# XHSC_HC32F420 register map
Vendor: XHSC Co.Ltd; Series: ARMCM4; File version: 1.2
CPU: CM4 r0p0, little endian, no MPU, no FPU, 3 interrupt priority bits
Registers are 32-bit, read-write, reset 0x0 unless marked. A register's access mark holds for its fields unless they carry their own. Offsets are from the block's base; [hi:lo] are bit positions; {n}, {i} and the like mark numbered series; 'fields as' and 'values as' point back to an identical list.

## I2C0 — desc I2C
Base 0x40002800
Same registers: I2C1 0x40002C00
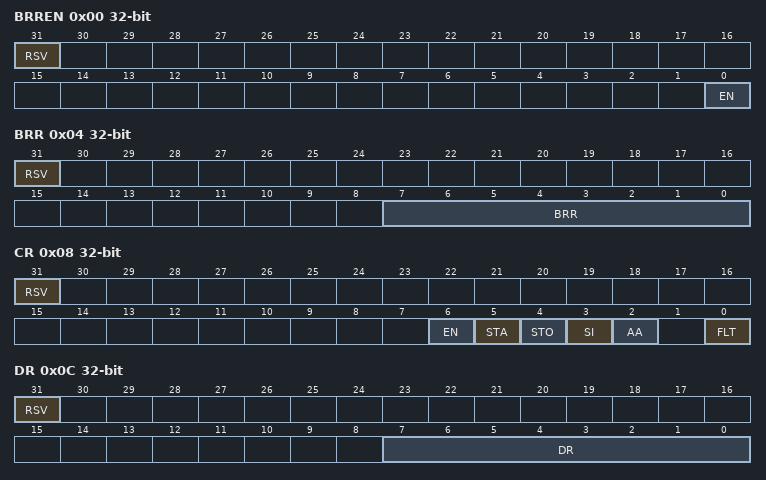
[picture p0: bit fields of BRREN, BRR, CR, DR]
0x00 BRREN (reset mask 0x1)
  [31] RSV, [0] EN
0x04 BRR (reset mask 0xFF)
  [31] RSV, [7:0] BRR
0x08 CR (reset mask 0x7D)
  [31] RSV, [6] EN, [5] STA, [4] STO, [3] SI, [2] AA, [0] FLT
0x0C DR (reset mask 0xFF)
  [31] RSV, [7:0] DR
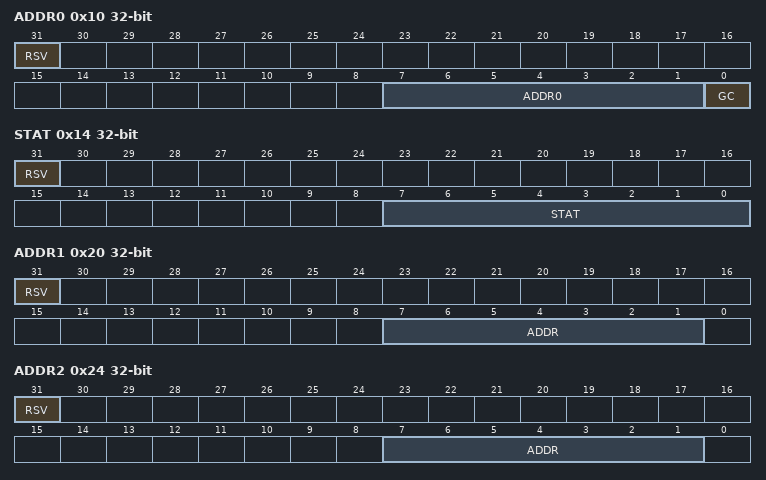
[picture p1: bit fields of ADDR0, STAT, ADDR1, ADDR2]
0x10 ADDR0 (reset mask 0xFF)
  [31] RSV, [7:1] ADDR0, [0] GC
0x14 STAT ro (reset mask 0xFF)
  [31] RSV, [7:0] STAT
0x20 ADDR1 (reset mask 0xFF)
  [31] RSV, [7:1] ADDR
0x24 ADDR2 (reset mask 0xFF)
  [31] RSV, [7:1] ADDR
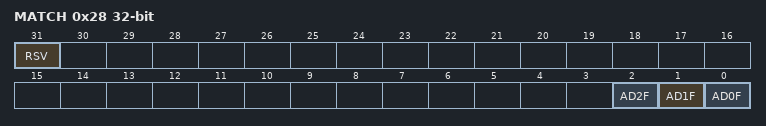
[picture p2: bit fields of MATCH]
0x28 MATCH ro (reset mask 0xFF)
  [31] RSV, [2] AD2F, [1] AD1F, [0] AD0F

## IWDT
Base 0x40008C80
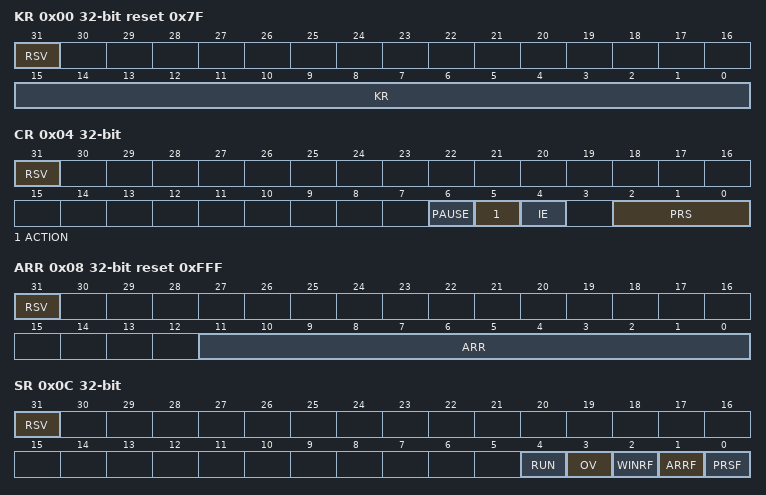
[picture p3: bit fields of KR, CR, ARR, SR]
0x00 KR wo reset 0x7F (reset mask 0xFF)
  [31] RSV, [15:0] KR
0x04 CR (reset mask 0xFF)
  [31] RSV, [6] PAUSE, [5] ACTION, [4] IE, [2:0] PRS
0x08 ARR reset 0xFFF (reset mask 0xFFF)
  [31] RSV, [11:0] ARR
0x0C SR (reset mask 0x1F)
  [31] RSV ro, [4] RUN ro, [3] OV, [2] WINRF ro, [1] ARRF ro, [0] PRSF ro
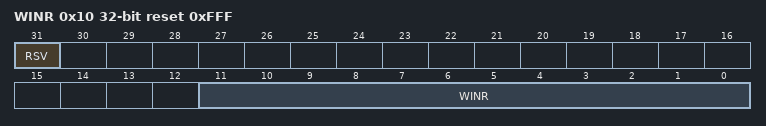
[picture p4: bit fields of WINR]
0x10 WINR reset 0xFFF (reset mask 0xFFF)
  [31] RSV, [11:0] WINR

## LVD
Base 0x4000AA00
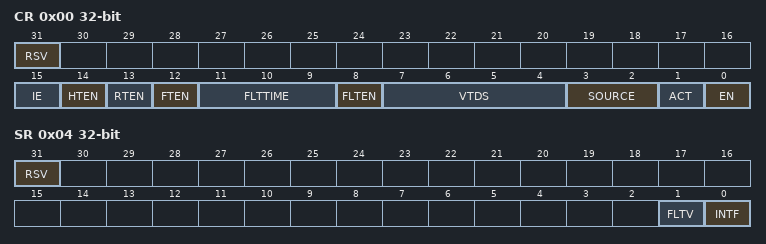
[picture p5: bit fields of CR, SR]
0x00 CR (reset mask 0xFFFF)
  [31] RSV, [15] IE, [14] HTEN, [13] RTEN, [12] FTEN, [11:9] FLTTIME, [8] FLTEN, [7:4] VTDS, [3:2] SOURCE, [1] ACT, [0] EN
0x04 SR (reset mask 0xFFFF)
  [31] RSV, [1] FLTV, [0] INTF

## SPI0 — desc SPI
Base 0x40003800
Same registers: SPI1 0x40003C00
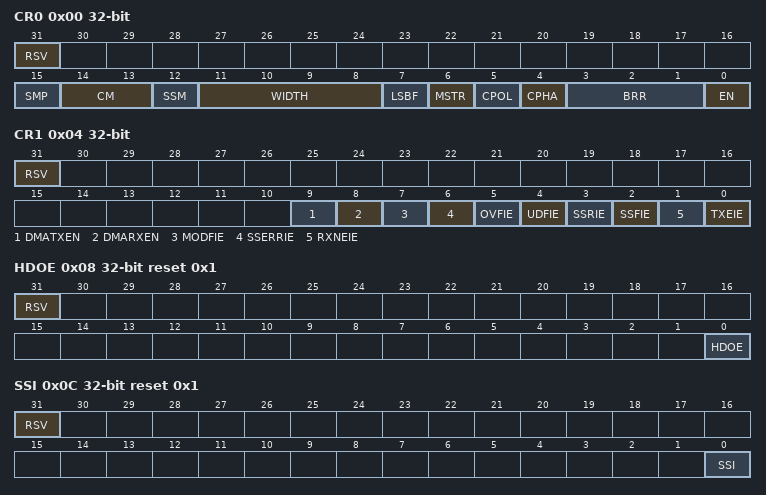
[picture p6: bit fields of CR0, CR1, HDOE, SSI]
0x00 CR0 (reset mask 0xDF)
  [31] RSV, [15] SMP, [14:13] CM, [12] SSM, [11:8] WIDTH, [7] LSBF, [6] MSTR, [5] CPOL, [4] CPHA, [3:1] BRR, [0] EN
0x04 CR1 (reset mask 0xDF)
  [31] RSV, [9] DMATXEN, [8] DMARXEN, [7] MODFIE, [6] SSERRIE, [5] OVFIE, [4] UDFIE, [3] SSRIE, [2] SSFIE, [1] RXNEIE, [0] TXEIE
0x08 HDOE reset 0x1 (reset mask 0x1)
  [31] RSV, [0] HDOE
0x0C SSI reset 0x1 (reset mask 0x1)
  [31] RSV, [0] SSI
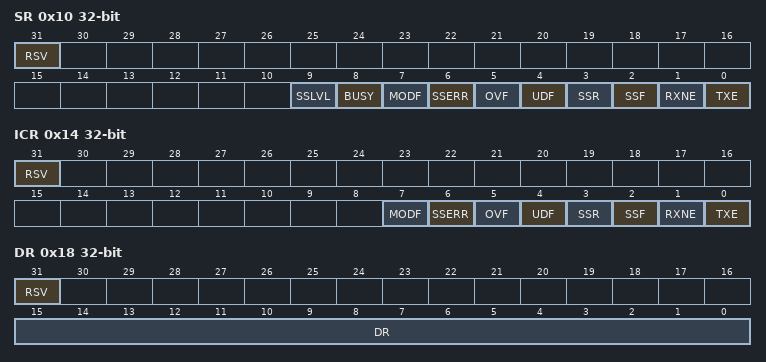
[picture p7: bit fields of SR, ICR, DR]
0x10 SR ro (reset mask 0xBE)
  [31] RSV, [9] SSLVL, [8] BUSY, [7] MODF, [6] SSERR, [5] OVF, [4] UDF, [3] SSR, [2] SSF, [1] RXNE, [0] TXE
0x14 ICR wo (reset mask 0xBE)
  [31] RSV, [7] MODF, [6] SSERR, [5] OVF, [4] UDF, [3] SSR, [2] SSF, [1] RXNE, [0] TXE
0x18 DR (reset mask 0xFF)
  [31] RSV, [15:0] DR

## SYSCTRL
Base 0x4000B800; alternate view of GPIOAUX
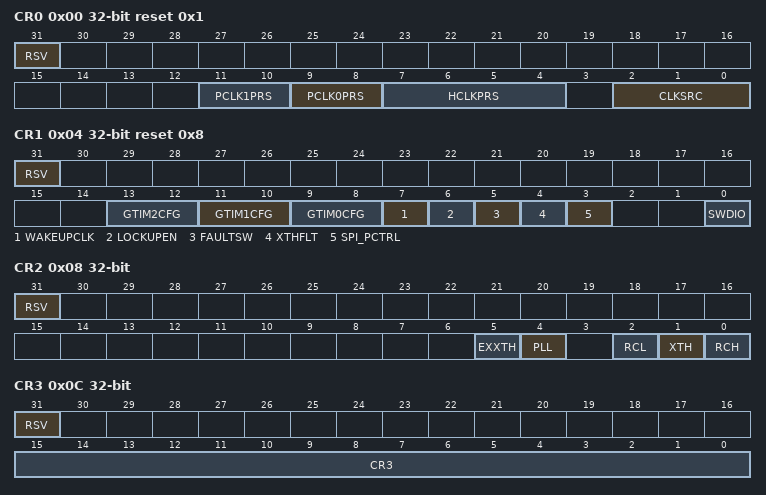
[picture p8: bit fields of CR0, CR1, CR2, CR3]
0x00 CR0 reset 0x1 (reset mask 0x9FFF)
  [31] RSV, [11:10] PCLK1PRS, [9:8] PCLK0PRS, [7:4] HCLKPRS, [2:0] CLKSRC
0x04 CR1 reset 0x8 (reset mask 0xF7E)
  [31] RSV, [13:12] GTIM2CFG, [11:10] GTIM1CFG, [9:8] GTIM0CFG, [7] WAKEUPCLK, [6] LOCKUPEN, [5] FAULTSW, [4] XTHFLT, [3] SPI_PCTRL, [0] SWDIO
0x08 CR2 (reset mask 0xFFFF)
  [31] RSV, [5] EXXTH, [4] PLL, [2] RCL, [1] XTH, [0] RCH
0x0C CR3 wo (reset mask 0xFFFF)
  [31] RSV, [15:0] CR3
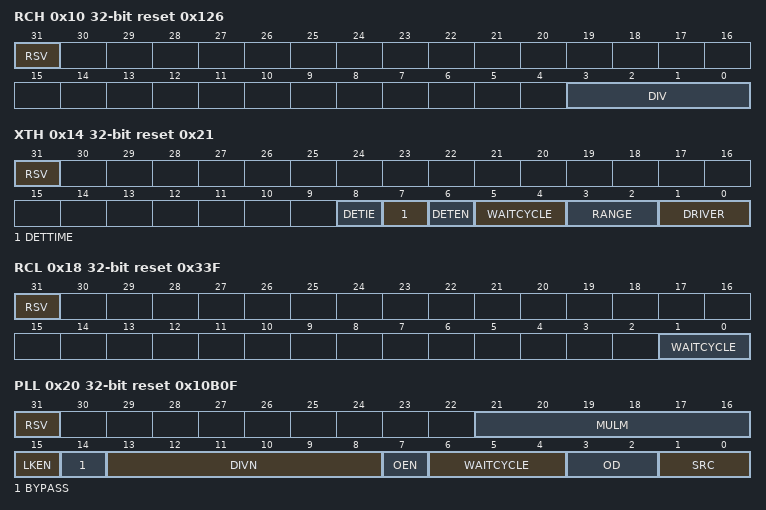
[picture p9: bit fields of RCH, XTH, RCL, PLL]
0x10 RCH reset 0x126 (reset mask 0xFFF)
  [31] RSV, [3:0] DIV
0x14 XTH reset 0x21 (reset mask 0x7F)
  [31] RSV, [8] DETIE, [7] DETTIME, [6] DETEN, [5:4] WAITCYCLE, [3:2] RANGE, [1:0] DRIVER
0x18 RCL reset 0x33F (reset mask 0x1FFF)
  [31] RSV, [1:0] WAITCYCLE
0x20 PLL reset 0x10B0F (reset mask 0x3FFFF)
  [31] RSV, [21:16] MULM, [15] LKEN, [14] BYPASS, [13:8] DIVN, [7] OEN, [6:4] WAITCYCLE, [3:2] OD, [1:0] SRC
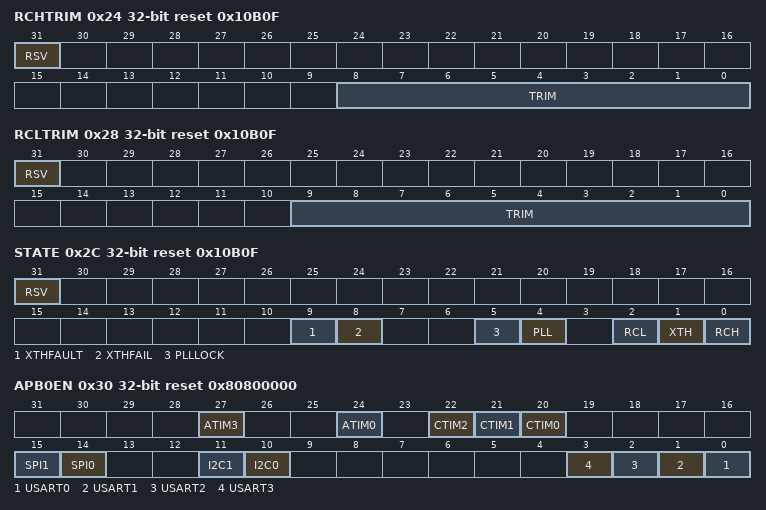
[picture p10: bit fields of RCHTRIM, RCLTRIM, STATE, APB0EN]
0x24 RCHTRIM reset 0x10B0F (reset mask 0x3FFFF)
  [31] RSV, [8:0] TRIM
0x28 RCLTRIM reset 0x10B0F (reset mask 0x3FFFF)
  [31] RSV, [9:0] TRIM
0x2C STATE reset 0x10B0F (reset mask 0x3FFFF)
  [31] RSV, [9] XTHFAULT, [8] XTHFAIL, [5] PLLLOCK, [4] PLL, [2] RCL, [1] XTH, [0] RCH
0x30 APB0EN reset 0x80800000
  [27] ATIM3, [24] ATIM0, [22] CTIM2, [21] CTIM1, [20] CTIM0, [15] SPI1, [14] SPI0, [11] I2C1, [10] I2C0, [n] USART{n} (n=0..3)
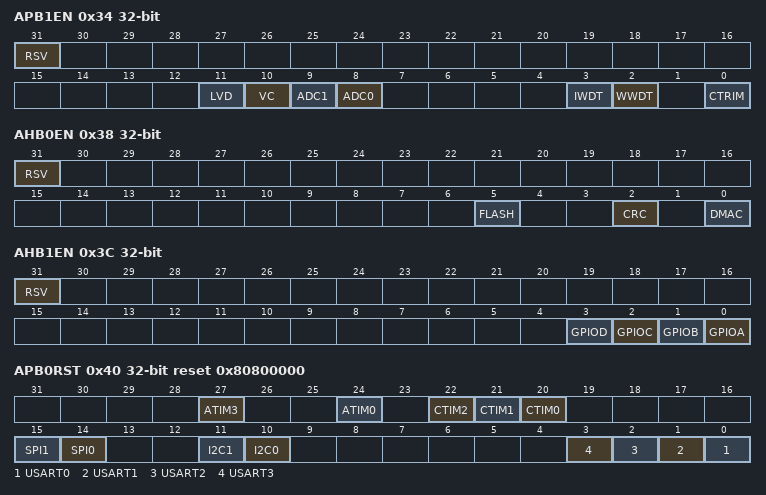
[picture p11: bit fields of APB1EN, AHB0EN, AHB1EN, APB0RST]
0x34 APB1EN (reset mask 0xFFF)
  [31] RSV, [11] LVD, [10] VC, [9] ADC1, [8] ADC0, [3] IWDT, [2] WWDT, [0] CTRIM
0x38 AHB0EN (reset mask 0xFFF)
  [31] RSV, [5] FLASH, [2] CRC, [0] DMAC
0x3C AHB1EN (reset mask 0xFFF)
  [31] RSV, [3] GPIOD, [2] GPIOC, [1] GPIOB, [0] GPIOA
0x40 APB0RST reset 0x80800000
  fields as APB0EN
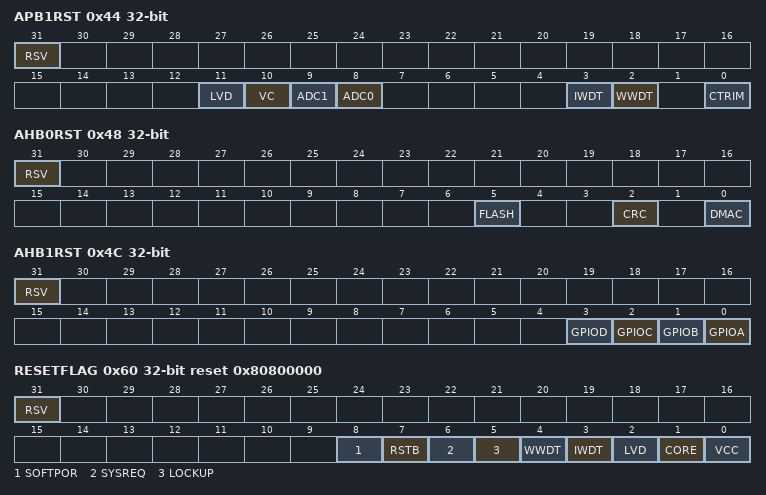
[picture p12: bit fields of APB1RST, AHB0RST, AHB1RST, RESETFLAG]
0x44 APB1RST (reset mask 0xFFF)
  fields as APB1EN
0x48 AHB0RST (reset mask 0xFFF)
  [31] RSV, [5] FLASH, [2] CRC, [0] DMAC
0x4C AHB1RST (reset mask 0xFFF)
  [31] RSV, [3] GPIOD, [2] GPIOC, [1] GPIOB, [0] GPIOA
0x60 RESETFLAG reset 0x80800000
  [31] RSV, [8] SOFTPOR, [7] RSTB, [6] SYSREQ, [5] LOCKUP, [4] WWDT, [3] IWDT, [2] LVD, [1] CORE, [0] VCC
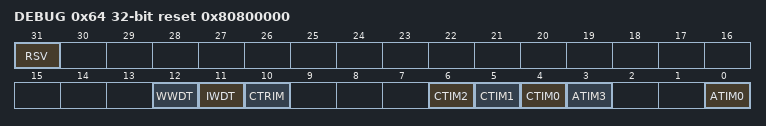
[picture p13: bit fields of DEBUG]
0x64 DEBUG reset 0x80800000 (reset mask 0xFF7FEFFF)
  [31] RSV, [12] WWDT, [11] IWDT, [10] CTRIM, [6] CTIM2, [5] CTIM1, [4] CTIM0, [3] ATIM3, [0] ATIM0

## USART0 — desc USART
Base 0x40000000
Same registers: USART1 0x40000400, USART2 0x40000800, USART3 0x40000C00
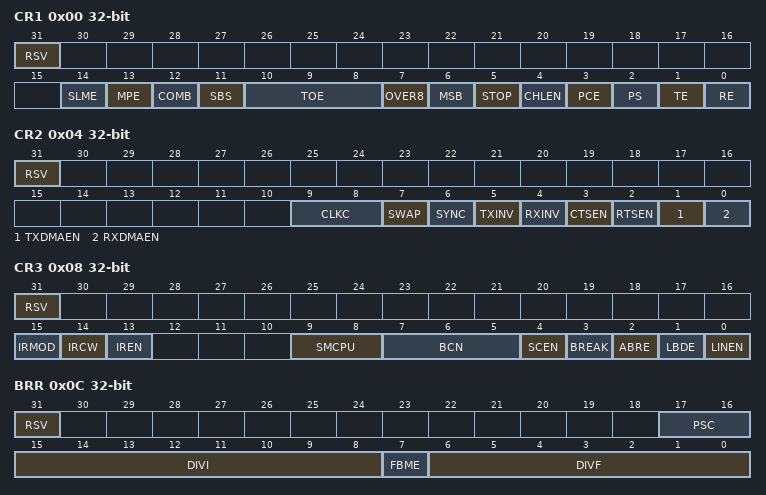
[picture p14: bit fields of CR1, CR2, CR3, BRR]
0x00 CR1 (reset mask 0xFFFF)
  [31] RSV, [14] SLME, [13] MPE, [12] COMB, [11] SBS, [10:8] TOE, [7] OVER8, [6] MSB, [5] STOP, [4] CHLEN, [3] PCE, [2] PS, [1] TE, [0] RE
0x04 CR2 (reset mask 0xFFFF)
  [31] RSV, [9:8] CLKC, [7] SWAP, [6] SYNC, [5] TXINV, [4] RXINV, [3] CTSEN, [2] RTSEN, [1] TXDMAEN, [0] RXDMAEN
0x08 CR3 (reset mask 0xFFFF)
  [31] RSV, [15] IRMOD, [14] IRCW, [13] IREN, [9:8] SMCPU, [7:5] BCN, [4] SCEN, [3] BREAK, [2] ABRE, [1] LBDE, [0] LINEN
0x0C BRR (reset mask 0xFFFF)
  [31] RSV, [17:16] PSC, [15:8] DIVI, [7] FBME, [6:0] DIVF
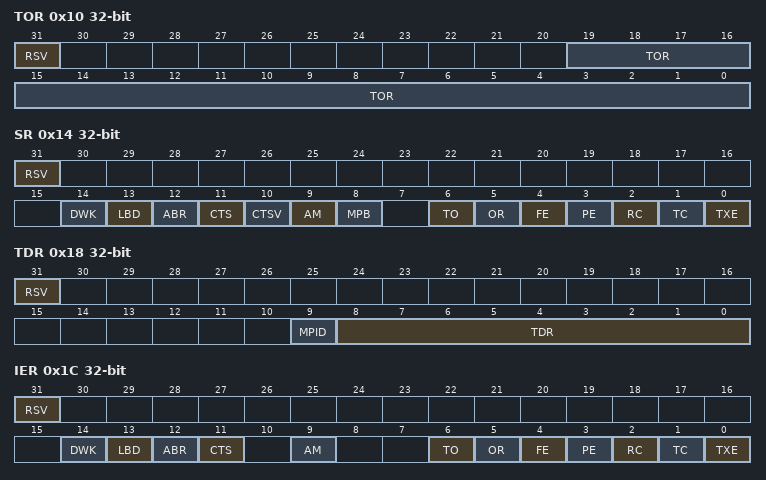
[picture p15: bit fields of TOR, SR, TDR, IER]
0x10 TOR (reset mask 0xFFFFF)
  [31] RSV, [19:0] TOR
0x14 SR ro (reset mask 0xFFFF)
  [31] RSV, [14] DWK, [13] LBD, [12] ABR, [11] CTS, [10] CTSV, [9] AM, [8] MPB, [6] TO, [5] OR, [4] FE, [3] PE, [2] RC, [1] TC, [0] TXE
0x18 TDR (reset mask 0xFFFF)
  [31] RSV, [9] MPID, [8:0] TDR
0x1C IER (reset mask 0xFFFF)
  [31] RSV, [14] DWK, [13] LBD, [12] ABR, [11] CTS, [9] AM, [6] TO, [5] OR, [4] FE, [3] PE, [2] RC, [1] TC, [0] TXE
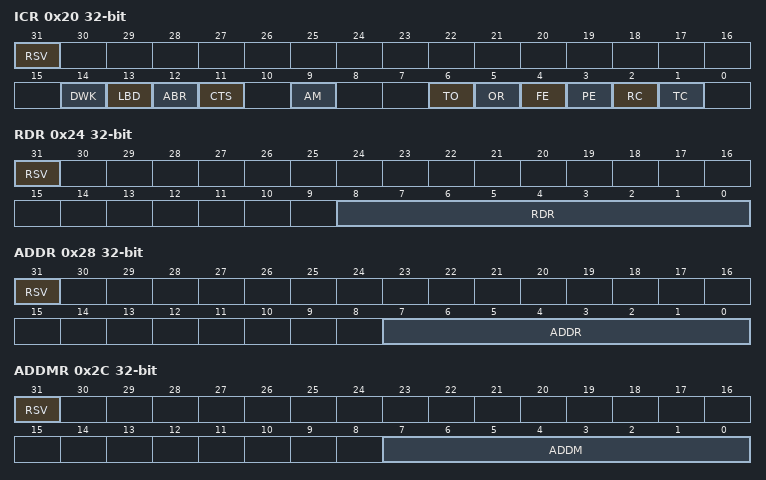
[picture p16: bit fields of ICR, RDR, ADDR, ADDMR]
0x20 ICR wo (reset mask 0xFFFF)
  [31] RSV, [14] DWK, [13] LBD, [12] ABR, [11] CTS, [9] AM, [6] TO, [5] OR, [4] FE, [3] PE, [2] RC, [1] TC
0x24 RDR ro (reset mask 0x1FF)
  [31] RSV, [8:0] RDR
0x28 ADDR (reset mask 0xFF)
  [31] RSV, [7:0] ADDR
0x2C ADDMR (reset mask 0xFF)
  [31] RSV, [7:0] ADDM
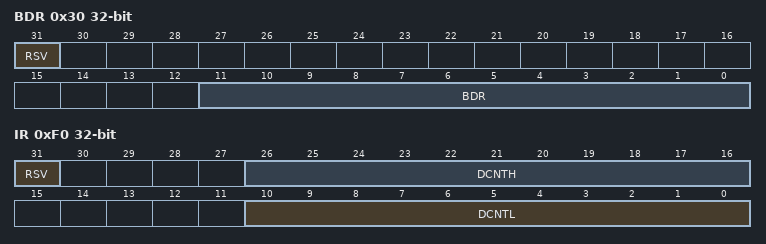
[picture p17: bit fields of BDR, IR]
0x30 BDR ro (reset mask 0xFFFF)
  [31] RSV, [11:0] BDR
0xF0 IR
  [31] RSV, [26:16] DCNTH, [10:0] DCNTL

## VC0 — desc VC
Base 0x4000A800
Same registers: VC1 0x4000A810
0x00 CR0 (reset mask 0x1FFFF)
  [31] RSV, [11:10] HYS, [9:8] BIAS, [7] REF, [6] DIVEN, [5:0] DIV
0x04 CR1 (reset mask 0x1FFFF)
  [31] RSV, [17] FLTCLK, [16] EN, [15] IE, [14] LEVEL, [13] RISING, [12] FALLING, [11:9] FLTTIME, [8] FLTEN, [7:4] NSEL, [3:0] PSEL
0x08 CR2 (reset mask 0x1FFFF)
  [31] RSV ro, [6] WINDOW, [5] ATIMBK, [4] ATIM3CLR, [1] ATIM0CLR, [0] POL
0x0C SR (reset mask 0xFE3F)
  [31] RSV, [1] FLTV ro, [0] INTF

## WWDT
Base 0x40008800
0x00 CR0 (reset mask 0xFF)
  [31] RSV, [7] EN, [6:0] WCNT
0x04 CR1 reset 0x7F (reset mask 0xFF)
  [31] RSV, [13:11] PRS, [9] IE, [6:0] WINR
0x08 SR (reset mask 0x1)
  [31] RSV, [0] POV
